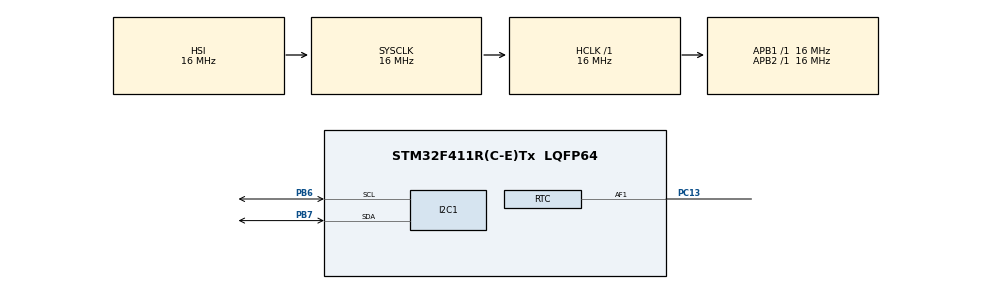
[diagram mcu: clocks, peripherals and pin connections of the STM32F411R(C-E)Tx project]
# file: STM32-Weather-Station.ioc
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Mcu.Family=STM32F4
Mcu.Name=STM32F411R(C-E)Tx
Mcu.Package=LQFP64
NVIC.PriorityGroup=NVIC_PRIORITYGROUP_0
NVIC.RTC_Alarm_IRQn=true\:0\:0\:false\:false\:true\:true\:true\:true
PB6.Mode=I2C
PB6.Signal=I2C1_SCL
PB7.Mode=I2C
PB7.Signal=I2C1_SDA
PC13-ANTI_TAMP.Mode=AlarmA_RoutedAF
PC13-ANTI_TAMP.Signal=RTC_AF1
PC14-OSC32_IN.Mode=LSE-External-Oscillator
PC14-OSC32_IN.Signal=RCC_OSC32_IN
PC15-OSC32_OUT.Mode=LSE-External-Oscillator
PC15-OSC32_OUT.Signal=RCC_OSC32_OUT
ProjectManager.HeapSize=0x200
ProjectManager.StackSize=0x400
ProjectManager.TargetToolchain=STM32CubeIDE
RCC.48MHZClocksFreq_Value=84000000
RCC.AHBFreq_Value=16000000
RCC.APB1Freq_Value=16000000
RCC.APB1TimFreq_Value=16000000
RCC.APB2Freq_Value=16000000
RCC.APB2TimFreq_Value=16000000
RCC.CortexFreq_Value=16000000
RCC.FLatency-AdvancedSettings=FLASH_LATENCY_0
RCC.HCLKFreq_Value=16000000
RCC.HSE_VALUE=8000000
RCC.HSI_VALUE=16000000
RCC.PLLN=336
RCC.PLLP=RCC_PLLP_DIV4
RCC.RCC_RTC_Clock_Source=RCC_RTCCLKSOURCE_LSE
RCC.SYSCLKFreq_VALUE=16000000
RCC.VCOOutputFreq_Value=336000000
RTC.Alarm=RTC_ALARM_A
VP_RTC_VS_RTC_Activate.Mode=RTC_Enabled
VP_RTC_VS_RTC_Calendar.Mode=RTC_Calendar
board=NUCLEO-F411RE

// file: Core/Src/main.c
/* USER CODE BEGIN Header */
/**
  ******************************************************************************
  * @file           : main.c
  * @brief          : Main program body
  ******************************************************************************
  * @attention
  *
  * Copyright (c) 2026 STMicroelectronics.
  * All rights reserved.
  *
  * This software is licensed under terms that can be found in the LICENSE file
  * in the root directory of this software component.
  * If no LICENSE file comes with this software, it is provided AS-IS.
  *
  ******************************************************************************
  */
/* USER CODE END Header */
#include "main.h"

I2C_HandleTypeDef hi2c1;

RTC_HandleTypeDef hrtc;

void SystemClock_Config(void);
static void MX_GPIO_Init(void);
static void MX_I2C1_Init(void);
static void MX_RTC_Init(void);

int main(void)
{

  /* MCU Configuration--------------------------------------------------------*/

  /* Reset of all peripherals, Initializes the Flash interface and the Systick. */
  HAL_Init();

  /* Configure the system clock */
  SystemClock_Config();

  /* Initialize all configured peripherals */
  MX_GPIO_Init();
  MX_I2C1_Init();
  MX_RTC_Init();
  /* USER CODE BEGIN 2 */

	uint8_t bme280_adress = 0x76 << 1;
	uint8_t chip_id = 0;

	HAL_StatusTypeDef status = HAL_I2C_Mem_Read(&hi2c1, bme280_adress, 0xD0, I2C_MEMADD_SIZE_8BIT, &chip_id, 1, 100);
	if(status != HAL_OK || chip_id != 0x60) {
		while(1);
	}

	uint8_t calib_data[6] = {0};
	HAL_I2C_Mem_Read(&hi2c1, bme280_adress, 0x88, I2C_MEMADD_SIZE_8BIT, calib_data, 6, 100);
	uint16_t dig_T1 = (calib_data[1] << 8) | calib_data[0];
	int16_t dig_T2 = (calib_data[3] << 8) | calib_data[2];
	int16_t dig_T3 = (calib_data[5] << 8) | calib_data[4];

	uint8_t wake_up_cmd = 0x21;
	uint8_t raw_temp_data[3] = {0};
	int32_t uncompensated_temp = 0;
	int32_t var1, var2, temperature;

  /* USER CODE END 2 */

  /* Infinite loop */
  /* USER CODE BEGIN WHILE */
  while (1)
  {
	HAL_I2C_Mem_Write(&hi2c1, bme280_adress, 0xF4, I2C_MEMADD_SIZE_8BIT, &wake_up_cmd, 1, 100);

	HAL_Delay(10);

	HAL_I2C_Mem_Read(&hi2c1, bme280_adress, 0xFA, I2C_MEMADD_SIZE_8BIT, raw_temp_data, 3, 100);

	uncompensated_temp = (raw_temp_data[0] << 12) | (raw_temp_data[1] << 4) | (raw_temp_data[2] >> 4);
	var1 = ((((uncompensated_temp >> 3) - ((int32_t)dig_T1 << 1))) * ((int32_t)dig_T2)) >> 11;

	var2 = (((((uncompensated_temp >> 4) - ((int32_t)dig_T1)) * ((uncompensated_temp >> 4) - ((int32_t)dig_T1))) >> 12) * ((int32_t)dig_T3)) >> 14;

	int32_t t_fine = var1 + var2;

	temperature = (t_fine * 5 + 128) >> 8;
    /* USER CODE END WHILE */

  }
}

void SystemClock_Config(void)
{
  RCC_OscInitTypeDef RCC_OscInitStruct = {0};
  RCC_ClkInitTypeDef RCC_ClkInitStruct = {0};

  /** Configure the main internal regulator output voltage
  */
  __HAL_RCC_PWR_CLK_ENABLE();
  __HAL_PWR_VOLTAGESCALING_CONFIG(PWR_REGULATOR_VOLTAGE_SCALE1);

  /** Initializes the RCC Oscillators according to the specified parameters
  * in the RCC_OscInitTypeDef structure.
  */
  RCC_OscInitStruct.OscillatorType = RCC_OSCILLATORTYPE_HSI|RCC_OSCILLATORTYPE_LSE;
  RCC_OscInitStruct.LSEState = RCC_LSE_ON;
  RCC_OscInitStruct.HSIState = RCC_HSI_ON;
  RCC_OscInitStruct.HSICalibrationValue = RCC_HSICALIBRATION_DEFAULT;
  RCC_OscInitStruct.PLL.PLLState = RCC_PLL_NONE;
  if (HAL_RCC_OscConfig(&RCC_OscInitStruct) != HAL_OK)
  {
    Error_Handler();
  }

  /** Initializes the CPU, AHB and APB buses clocks
  */
  RCC_ClkInitStruct.ClockType = RCC_CLOCKTYPE_HCLK|RCC_CLOCKTYPE_SYSCLK
                              |RCC_CLOCKTYPE_PCLK1|RCC_CLOCKTYPE_PCLK2;
  RCC_ClkInitStruct.SYSCLKSource = RCC_SYSCLKSOURCE_HSI;
  RCC_ClkInitStruct.AHBCLKDivider = RCC_SYSCLK_DIV1;
  RCC_ClkInitStruct.APB1CLKDivider = RCC_HCLK_DIV1;
  RCC_ClkInitStruct.APB2CLKDivider = RCC_HCLK_DIV1;

  if (HAL_RCC_ClockConfig(&RCC_ClkInitStruct, FLASH_LATENCY_0) != HAL_OK)
  {
    Error_Handler();
  }
}

static void MX_I2C1_Init(void)
{

  hi2c1.Instance = I2C1;
  hi2c1.Init.ClockSpeed = 100000;
  hi2c1.Init.DutyCycle = I2C_DUTYCYCLE_2;
  hi2c1.Init.OwnAddress1 = 0;
  hi2c1.Init.AddressingMode = I2C_ADDRESSINGMODE_7BIT;
  hi2c1.Init.DualAddressMode = I2C_DUALADDRESS_DISABLE;
  hi2c1.Init.OwnAddress2 = 0;
  hi2c1.Init.GeneralCallMode = I2C_GENERALCALL_DISABLE;
  hi2c1.Init.NoStretchMode = I2C_NOSTRETCH_DISABLE;
  if (HAL_I2C_Init(&hi2c1) != HAL_OK)
  {
    Error_Handler();
  }

}

static void MX_RTC_Init(void)
{

  RTC_TimeTypeDef sTime = {0};
  RTC_DateTypeDef sDate = {0};

  /** Initialize RTC Only
  */
  hrtc.Instance = RTC;
  hrtc.Init.HourFormat = RTC_HOURFORMAT_24;
  hrtc.Init.AsynchPrediv = 127;
  hrtc.Init.SynchPrediv = 255;
  hrtc.Init.OutPut = RTC_OUTPUT_DISABLE;
  hrtc.Init.OutPutPolarity = RTC_OUTPUT_POLARITY_HIGH;
  hrtc.Init.OutPutType = RTC_OUTPUT_TYPE_OPENDRAIN;
  if (HAL_RTC_Init(&hrtc) != HAL_OK)
  {
    Error_Handler();
  }

  /** Initialize RTC and set the Time and Date
  */
  sTime.Hours = 0x0;
  sTime.Minutes = 0x0;
  sTime.Seconds = 0x0;
  sTime.DayLightSaving = RTC_DAYLIGHTSAVING_NONE;
  sTime.StoreOperation = RTC_STOREOPERATION_RESET;
  if (HAL_RTC_SetTime(&hrtc, &sTime, RTC_FORMAT_BCD) != HAL_OK)
  {
    Error_Handler();
  }
  sDate.WeekDay = RTC_WEEKDAY_MONDAY;
  sDate.Month = RTC_MONTH_JANUARY;
  sDate.Date = 0x1;
  sDate.Year = 0x0;

  if (HAL_RTC_SetDate(&hrtc, &sDate, RTC_FORMAT_BCD) != HAL_OK)
  {
    Error_Handler();
  }

}

static void MX_GPIO_Init(void)
{

  /* GPIO Ports Clock Enable */
  __HAL_RCC_GPIOC_CLK_ENABLE();
  __HAL_RCC_GPIOB_CLK_ENABLE();

}

void Error_Handler(void)
{
  __disable_irq();
  while (1)
  {
  }
}
